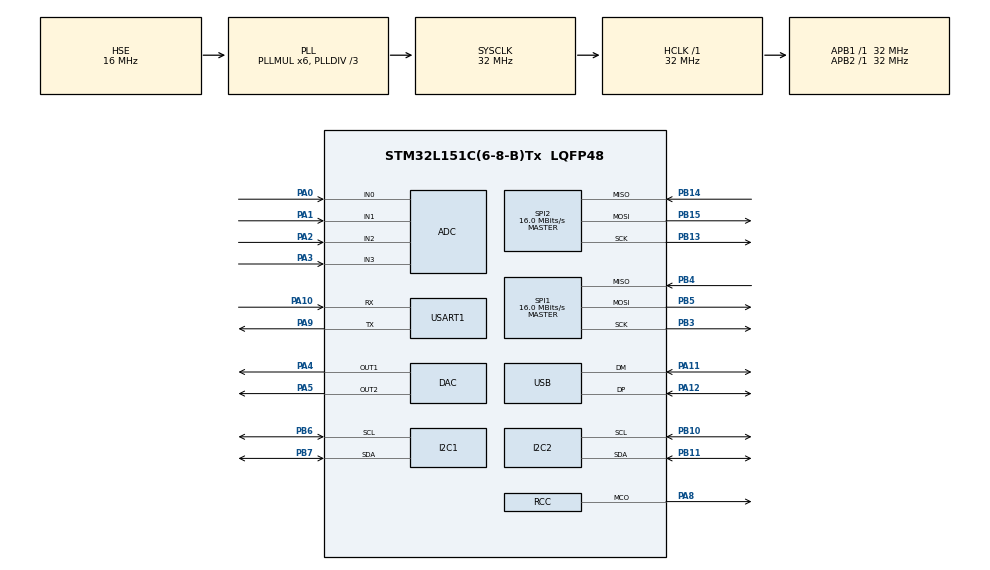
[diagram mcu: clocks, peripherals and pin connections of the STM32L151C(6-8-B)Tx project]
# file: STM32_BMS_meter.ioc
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ADC.Channel-1\#ChannelRegularConversion=ADC_CHANNEL_3
ADC.NbrOfConversionFlag=1
ADC.Rank-1\#ChannelRegularConversion=1
ADC.SamplingTime-1\#ChannelRegularConversion=ADC_SAMPLETIME_4CYCLES
Mcu.Family=STM32L1
Mcu.Name=STM32L151C(6-8-B)Tx
Mcu.Package=LQFP48
NVIC.PriorityGroup=NVIC_PRIORITYGROUP_4
PA0-WKUP1.Mode=IN0
PA0-WKUP1.Signal=ADC_IN0
PA1.Mode=IN1
PA1.Signal=ADC_IN1
PA10.Mode=Asynchronous
PA10.Signal=USART1_RX
PA11.Mode=Device
PA11.Signal=USB_DM
PA12.Mode=Device
PA12.Signal=USB_DP
PA13.Mode=Serial_Wire
PA13.Signal=SYS_JTMS-SWDIO
PA14.Mode=Serial_Wire
PA14.Signal=SYS_JTCK-SWCLK
PA2.Mode=IN2
PA2.Signal=ADC_IN2
PA3.Mode=IN3
PA3.Signal=ADC_IN3
PA4.Signal=COMP_DAC1_group
PA5.Signal=COMP_DAC2_group
PA8.Mode=Clock-out
PA8.Signal=RCC_MCO
PA9.Mode=Asynchronous
PA9.Signal=USART1_TX
PB10.Mode=I2C
PB10.Signal=I2C2_SCL
PB11.Mode=I2C
PB11.Signal=I2C2_SDA
PB13.Mode=Full_Duplex_Master
PB13.Signal=SPI2_SCK
PB14.Mode=Full_Duplex_Master
PB14.Signal=SPI2_MISO
PB15.Mode=Full_Duplex_Master
PB15.Signal=SPI2_MOSI
PB3.Mode=Full_Duplex_Master
PB3.Signal=SPI1_SCK
PB4.Mode=Full_Duplex_Master
PB4.Signal=SPI1_MISO
PB5.Mode=Full_Duplex_Master
PB5.Signal=SPI1_MOSI
PB6.Mode=I2C
PB6.Signal=I2C1_SCL
PB7.Mode=I2C
PB7.Signal=I2C1_SDA
PH0-OSC_IN.Mode=HSE-External-Oscillator
PH0-OSC_IN.Signal=RCC_OSC_IN
PH1-OSC_OUT.Mode=HSE-External-Oscillator
PH1-OSC_OUT.Signal=RCC_OSC_OUT
ProjectManager.HeapSize=0x200
ProjectManager.StackSize=0x400
ProjectManager.TargetToolchain=STM32CubeIDE
RCC.48MHZClocksFreq_Value=48000000
RCC.AHBFreq_Value=32000000
RCC.APB1Freq_Value=32000000
RCC.APB1TimFreq_Value=32000000
RCC.APB2Freq_Value=32000000
RCC.APB2TimFreq_Value=32000000
RCC.HCLKFreq_Value=32000000
RCC.HSE_VALUE=16000000
RCC.HSI_VALUE=16000000
RCC.MSI_VALUE=2097000
RCC.PLLDIV=RCC_PLL_DIV3
RCC.PLLMUL=RCC_PLL_MUL6
RCC.SYSCLKFreq_VALUE=32000000
RCC.SYSCLKSource=RCC_SYSCLKSOURCE_PLLCLK
RCC.VCOOutputFreq_Value=96000000
SH.COMP_DAC1_group.0=DAC_OUT1,DAC_OUT1
SH.COMP_DAC2_group.0=DAC_OUT2,DAC_OUT2
SPI1.CalculateBaudRate=16.0 MBits/s
SPI1.Direction=SPI_DIRECTION_2LINES
SPI1.Mode=SPI_MODE_MASTER
SPI1.VirtualType=VM_MASTER
SPI2.CalculateBaudRate=16.0 MBits/s
SPI2.Direction=SPI_DIRECTION_2LINES
SPI2.Mode=SPI_MODE_MASTER
SPI2.VirtualType=VM_MASTER
USART1.VirtualMode=VM_ASYNC
VP_RTC_VS_RTC_Activate.Mode=RTC_Enabled
board=custom

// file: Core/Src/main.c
/* USER CODE BEGIN Header */
/**
  ******************************************************************************
  * @file           : main.c
  * @brief          : Main program body
  ******************************************************************************
  * @attention
  *
  * Copyright (c) 2022 STMicroelectronics.
  * All rights reserved.
  *
  * This software is licensed under terms that can be found in the LICENSE file
  * in the root directory of this software component.
  * If no LICENSE file comes with this software, it is provided AS-IS.
  *
  ******************************************************************************
  */
/* USER CODE END Header */
#include "main.h"

/* USER CODE BEGIN Includes */

uint8_t DischargeCurrent ;

/* USER CODE END Includes */

ADC_HandleTypeDef hadc;

DAC_HandleTypeDef hdac;

I2C_HandleTypeDef hi2c1;
I2C_HandleTypeDef hi2c2;

RTC_HandleTypeDef hrtc;

SPI_HandleTypeDef hspi1;
SPI_HandleTypeDef hspi2;

UART_HandleTypeDef huart1;

PCD_HandleTypeDef hpcd_USB_FS;

void SystemClock_Config(void);
static void MX_GPIO_Init(void);
static void MX_DAC_Init(void);
static void MX_SPI1_Init(void);
static void MX_USART1_UART_Init(void);
static void MX_USB_PCD_Init(void);
static void MX_ADC_Init(void);
static void MX_I2C1_Init(void);
static void MX_I2C2_Init(void);
static void MX_RTC_Init(void);
static void MX_SPI2_Init(void);

int main(void)
{

  /* MCU Configuration--------------------------------------------------------*/

  /* Reset of all peripherals, Initializes the Flash interface and the Systick. */
  HAL_Init();

  /* Configure the system clock */
  SystemClock_Config();

  /* Initialize all configured peripherals */
  MX_GPIO_Init();
  MX_DAC_Init();
  MX_SPI1_Init();
  MX_USART1_UART_Init();
  MX_USB_PCD_Init();
  MX_ADC_Init();
  MX_I2C1_Init();
  MX_I2C2_Init();
  MX_RTC_Init();
  MX_SPI2_Init();

  /* Infinite loop */
  while (1)
  {

  }
}

void SystemClock_Config(void)
{
  RCC_OscInitTypeDef RCC_OscInitStruct = {0};
  RCC_ClkInitTypeDef RCC_ClkInitStruct = {0};
  RCC_PeriphCLKInitTypeDef PeriphClkInit = {0};

  /** Configure the main internal regulator output voltage
  */
  __HAL_PWR_VOLTAGESCALING_CONFIG(PWR_REGULATOR_VOLTAGE_SCALE1);
  /** Initializes the RCC Oscillators according to the specified parameters
  * in the RCC_OscInitTypeDef structure.
  */
  RCC_OscInitStruct.OscillatorType = RCC_OSCILLATORTYPE_HSI|RCC_OSCILLATORTYPE_LSI
                              |RCC_OSCILLATORTYPE_HSE;
  RCC_OscInitStruct.HSEState = RCC_HSE_ON;
  RCC_OscInitStruct.HSIState = RCC_HSI_ON;
  RCC_OscInitStruct.HSICalibrationValue = RCC_HSICALIBRATION_DEFAULT;
  RCC_OscInitStruct.LSIState = RCC_LSI_ON;
  RCC_OscInitStruct.PLL.PLLState = RCC_PLL_ON;
  RCC_OscInitStruct.PLL.PLLSource = RCC_PLLSOURCE_HSE;
  RCC_OscInitStruct.PLL.PLLMUL = RCC_PLL_MUL6;
  RCC_OscInitStruct.PLL.PLLDIV = RCC_PLL_DIV3;
  if (HAL_RCC_OscConfig(&RCC_OscInitStruct) != HAL_OK)
  {
    Error_Handler();
  }
  /** Initializes the CPU, AHB and APB buses clocks
  */
  RCC_ClkInitStruct.ClockType = RCC_CLOCKTYPE_HCLK|RCC_CLOCKTYPE_SYSCLK
                              |RCC_CLOCKTYPE_PCLK1|RCC_CLOCKTYPE_PCLK2;
  RCC_ClkInitStruct.SYSCLKSource = RCC_SYSCLKSOURCE_PLLCLK;
  RCC_ClkInitStruct.AHBCLKDivider = RCC_SYSCLK_DIV1;
  RCC_ClkInitStruct.APB1CLKDivider = RCC_HCLK_DIV1;
  RCC_ClkInitStruct.APB2CLKDivider = RCC_HCLK_DIV1;

  if (HAL_RCC_ClockConfig(&RCC_ClkInitStruct, FLASH_LATENCY_1) != HAL_OK)
  {
    Error_Handler();
  }
  PeriphClkInit.PeriphClockSelection = RCC_PERIPHCLK_RTC;
  PeriphClkInit.RTCClockSelection = RCC_RTCCLKSOURCE_LSI;
  if (HAL_RCCEx_PeriphCLKConfig(&PeriphClkInit) != HAL_OK)
  {
    Error_Handler();
  }
  HAL_RCC_MCOConfig(RCC_MCO1, RCC_MCO1SOURCE_SYSCLK, RCC_MCODIV_1);
}

static void MX_ADC_Init(void)
{

  ADC_ChannelConfTypeDef sConfig = {0};

  /** Configure the global features of the ADC (Clock, Resolution, Data Alignment and number of conversion)
  */
  hadc.Instance = ADC1;
  hadc.Init.ClockPrescaler = ADC_CLOCK_ASYNC_DIV1;
  hadc.Init.Resolution = ADC_RESOLUTION_12B;
  hadc.Init.DataAlign = ADC_DATAALIGN_RIGHT;
  hadc.Init.ScanConvMode = ADC_SCAN_DISABLE;
  hadc.Init.EOCSelection = ADC_EOC_SEQ_CONV;
  hadc.Init.LowPowerAutoWait = ADC_AUTOWAIT_DISABLE;
  hadc.Init.LowPowerAutoPowerOff = ADC_AUTOPOWEROFF_DISABLE;
  hadc.Init.ChannelsBank = ADC_CHANNELS_BANK_A;
  hadc.Init.ContinuousConvMode = DISABLE;
  hadc.Init.NbrOfConversion = 1;
  hadc.Init.DiscontinuousConvMode = DISABLE;
  hadc.Init.ExternalTrigConv = ADC_SOFTWARE_START;
  hadc.Init.ExternalTrigConvEdge = ADC_EXTERNALTRIGCONVEDGE_NONE;
  hadc.Init.DMAContinuousRequests = DISABLE;
  if (HAL_ADC_Init(&hadc) != HAL_OK)
  {
    Error_Handler();
  }
  /** Configure for the selected ADC regular channel its corresponding rank in the sequencer and its sample time.
  */
  sConfig.Channel = ADC_CHANNEL_3;
  sConfig.Rank = ADC_REGULAR_RANK_1;
  sConfig.SamplingTime = ADC_SAMPLETIME_4CYCLES;
  if (HAL_ADC_ConfigChannel(&hadc, &sConfig) != HAL_OK)
  {
    Error_Handler();
  }

}

static void MX_DAC_Init(void)
{

  DAC_ChannelConfTypeDef sConfig = {0};

  /** DAC Initialization
  */
  hdac.Instance = DAC;
  if (HAL_DAC_Init(&hdac) != HAL_OK)
  {
    Error_Handler();
  }
  /** DAC channel OUT1 config
  */
  sConfig.DAC_Trigger = DAC_TRIGGER_NONE;
  sConfig.DAC_OutputBuffer = DAC_OUTPUTBUFFER_ENABLE;
  if (HAL_DAC_ConfigChannel(&hdac, &sConfig, DAC_CHANNEL_1) != HAL_OK)
  {
    Error_Handler();
  }
  /** DAC channel OUT2 config
  */
  if (HAL_DAC_ConfigChannel(&hdac, &sConfig, DAC_CHANNEL_2) != HAL_OK)
  {
    Error_Handler();
  }

}

static void MX_I2C1_Init(void)
{

  hi2c1.Instance = I2C1;
  hi2c1.Init.ClockSpeed = 100000;
  hi2c1.Init.DutyCycle = I2C_DUTYCYCLE_2;
  hi2c1.Init.OwnAddress1 = 0;
  hi2c1.Init.AddressingMode = I2C_ADDRESSINGMODE_7BIT;
  hi2c1.Init.DualAddressMode = I2C_DUALADDRESS_DISABLE;
  hi2c1.Init.OwnAddress2 = 0;
  hi2c1.Init.GeneralCallMode = I2C_GENERALCALL_DISABLE;
  hi2c1.Init.NoStretchMode = I2C_NOSTRETCH_DISABLE;
  if (HAL_I2C_Init(&hi2c1) != HAL_OK)
  {
    Error_Handler();
  }

}

static void MX_I2C2_Init(void)
{

  hi2c2.Instance = I2C2;
  hi2c2.Init.ClockSpeed = 100000;
  hi2c2.Init.DutyCycle = I2C_DUTYCYCLE_2;
  hi2c2.Init.OwnAddress1 = 0;
  hi2c2.Init.AddressingMode = I2C_ADDRESSINGMODE_7BIT;
  hi2c2.Init.DualAddressMode = I2C_DUALADDRESS_DISABLE;
  hi2c2.Init.OwnAddress2 = 0;
  hi2c2.Init.GeneralCallMode = I2C_GENERALCALL_DISABLE;
  hi2c2.Init.NoStretchMode = I2C_NOSTRETCH_DISABLE;
  if (HAL_I2C_Init(&hi2c2) != HAL_OK)
  {
    Error_Handler();
  }

}

static void MX_RTC_Init(void)
{

  /** Initialize RTC Only
  */
  hrtc.Instance = RTC;
  hrtc.Init.HourFormat = RTC_HOURFORMAT_24;
  hrtc.Init.AsynchPrediv = 127;
  hrtc.Init.SynchPrediv = 255;
  hrtc.Init.OutPut = RTC_OUTPUT_DISABLE;
  hrtc.Init.OutPutPolarity = RTC_OUTPUT_POLARITY_HIGH;
  hrtc.Init.OutPutType = RTC_OUTPUT_TYPE_OPENDRAIN;
  if (HAL_RTC_Init(&hrtc) != HAL_OK)
  {
    Error_Handler();
  }

}

static void MX_SPI1_Init(void)
{

  /* SPI1 parameter configuration*/
  hspi1.Instance = SPI1;
  hspi1.Init.Mode = SPI_MODE_MASTER;
  hspi1.Init.Direction = SPI_DIRECTION_2LINES;
  hspi1.Init.DataSize = SPI_DATASIZE_8BIT;
  hspi1.Init.CLKPolarity = SPI_POLARITY_LOW;
  hspi1.Init.CLKPhase = SPI_PHASE_1EDGE;
  hspi1.Init.NSS = SPI_NSS_SOFT;
  hspi1.Init.BaudRatePrescaler = SPI_BAUDRATEPRESCALER_2;
  hspi1.Init.FirstBit = SPI_FIRSTBIT_MSB;
  hspi1.Init.TIMode = SPI_TIMODE_DISABLE;
  hspi1.Init.CRCCalculation = SPI_CRCCALCULATION_DISABLE;
  hspi1.Init.CRCPolynomial = 10;
  if (HAL_SPI_Init(&hspi1) != HAL_OK)
  {
    Error_Handler();
  }

}

static void MX_SPI2_Init(void)
{

  /* SPI2 parameter configuration*/
  hspi2.Instance = SPI2;
  hspi2.Init.Mode = SPI_MODE_MASTER;
  hspi2.Init.Direction = SPI_DIRECTION_2LINES;
  hspi2.Init.DataSize = SPI_DATASIZE_8BIT;
  hspi2.Init.CLKPolarity = SPI_POLARITY_LOW;
  hspi2.Init.CLKPhase = SPI_PHASE_1EDGE;
  hspi2.Init.NSS = SPI_NSS_SOFT;
  hspi2.Init.BaudRatePrescaler = SPI_BAUDRATEPRESCALER_2;
  hspi2.Init.FirstBit = SPI_FIRSTBIT_MSB;
  hspi2.Init.TIMode = SPI_TIMODE_DISABLE;
  hspi2.Init.CRCCalculation = SPI_CRCCALCULATION_DISABLE;
  hspi2.Init.CRCPolynomial = 10;
  if (HAL_SPI_Init(&hspi2) != HAL_OK)
  {
    Error_Handler();
  }

}

static void MX_USART1_UART_Init(void)
{

  huart1.Instance = USART1;
  huart1.Init.BaudRate = 115200;
  huart1.Init.WordLength = UART_WORDLENGTH_8B;
  huart1.Init.StopBits = UART_STOPBITS_1;
  huart1.Init.Parity = UART_PARITY_NONE;
  huart1.Init.Mode = UART_MODE_TX_RX;
  huart1.Init.HwFlowCtl = UART_HWCONTROL_NONE;
  huart1.Init.OverSampling = UART_OVERSAMPLING_16;
  if (HAL_UART_Init(&huart1) != HAL_OK)
  {
    Error_Handler();
  }

}

static void MX_USB_PCD_Init(void)
{

  hpcd_USB_FS.Instance = USB;
  hpcd_USB_FS.Init.dev_endpoints = 8;
  hpcd_USB_FS.Init.speed = PCD_SPEED_FULL;
  hpcd_USB_FS.Init.phy_itface = PCD_PHY_EMBEDDED;
  hpcd_USB_FS.Init.low_power_enable = DISABLE;
  hpcd_USB_FS.Init.battery_charging_enable = DISABLE;
  if (HAL_PCD_Init(&hpcd_USB_FS) != HAL_OK)
  {
    Error_Handler();
  }

}

static void MX_GPIO_Init(void)
{
  GPIO_InitTypeDef GPIO_InitStruct = {0};

  /* GPIO Ports Clock Enable */
  __HAL_RCC_GPIOH_CLK_ENABLE();
  __HAL_RCC_GPIOA_CLK_ENABLE();
  __HAL_RCC_GPIOB_CLK_ENABLE();

  /*Configure GPIO pin : PA8 */
  GPIO_InitStruct.Pin = GPIO_PIN_8;
  GPIO_InitStruct.Mode = GPIO_MODE_AF_PP;
  GPIO_InitStruct.Pull = GPIO_NOPULL;
  GPIO_InitStruct.Speed = GPIO_SPEED_FREQ_LOW;
  GPIO_InitStruct.Alternate = GPIO_AF0_MCO;
  HAL_GPIO_Init(GPIOA, &GPIO_InitStruct);

}

void Error_Handler(void)
{
  __disable_irq();
  while (1)
  {
  }
}
